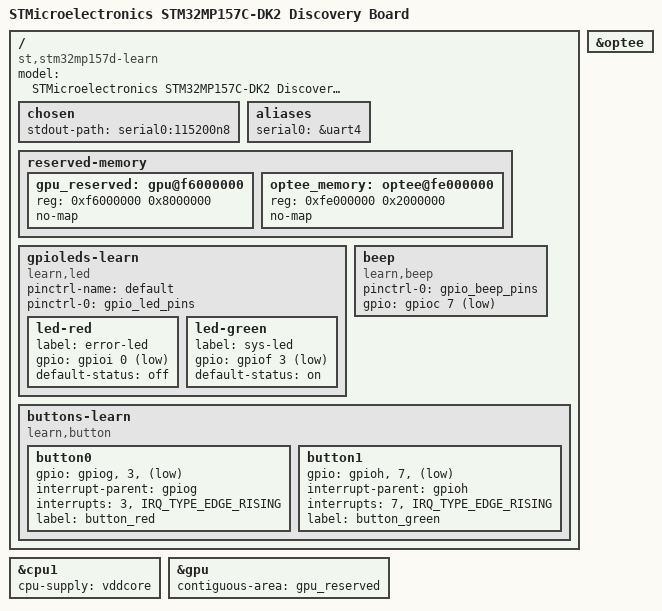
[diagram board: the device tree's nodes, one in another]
// SPDX-License-Identifier: (GPL-2.0+ OR BSD-3-Clause)
/*
 * Copyright (C) STMicroelectronics 2019 - All Rights Reserved
 * Author: Alexandre Torgue <alexandre.torgue@st.com> for STMicroelectronics.
 */

/dts-v1/;

#include "stm32mp157.dtsi"
#include "stm32mp15xd.dtsi"
#include "stm32mp15-pinctrl.dtsi"
#include "stm32mp15xxaa-pinctrl.dtsi"
#include "stm32mp157-m4-srm.dtsi"
#include "stm32mp157-m4-srm-pinctrl.dtsi"
#include "stm32mp157d-learn.dtsi"

/ {
	model = "STMicroelectronics STM32MP157C-DK2 Discovery Board";
	compatible = "st,stm32mp157d-learn", "st,stm32mp157";

	chosen {
		stdout-path = "serial0:115200n8";
	};

	aliases {
		serial0 = &uart4;
	};

	reserved-memory {
		gpu_reserved: gpu@f6000000 {
			reg = <0xf6000000 0x8000000>;
			no-map;
		};

        optee_memory: optee@fe000000 {
			reg = <0xfe000000 0x2000000>;
			no-map;
        };
	};

	gpioleds-learn{
		compatible = "learn,led";
		pinctrl-name = "default";
		pinctrl-0 = <&gpio_led_pins>;
		status = "okay";
		led-red {
			label = "error-led";
			gpio = <&gpioi 0 GPIO_ACTIVE_LOW>;
			default-status = "off";
		};
		led-green {
			label = "sys-led";
			gpio = <&gpiof 3 GPIO_ACTIVE_LOW>;
			default-status = "on";
		};
	};

	beep {
		compatible = "learn,beep";
		status = "okay";
		pinctrl-names = "default";
		pinctrl-0 = <&gpio_beep_pins>;
		gpio = <&gpioc 7 GPIO_ACTIVE_LOW>;
	};

	buttons-learn {
		compatible = "learn,button";
		status = "okay";
		button0{
			gpio = <&gpiog, 3, GPIO_ACTIVE_LOW>;
			interrupt-parent = <&gpiog>;
			interrupts = <3, IRQ_TYPE_EDGE_RISING>;
			label = "button_red";
		};
		button1{
			gpio = <&gpioh, 7, GPIO_ACTIVE_LOW>;
			interrupt-parent = <&gpioh>;
			interrupts = <7, IRQ_TYPE_EDGE_RISING>;
			label = "button_green";
		};
	};
};

&cpu1{
    cpu-supply = <&vddcore>;
};

&gpu{
    contiguous-area = <&gpu_reserved>;
    status = "okay";
};

&optee {
    status = "okay";
};
